# CC3200 register map
Vendor: Texas Instruments; Series: SimpleLink; File version: 1.0
CPU: CM4 r0p1, little endian, MPU, no FPU, 3 interrupt priority bits
Registers are 32-bit, read-write, reset 0x0 unless marked. A register's access mark holds for its fields unless they carry their own. Offsets are from the block's base; [hi:lo] are bit positions; {n}, {i} and the like mark numbered series; 'fields as' and 'values as' point back to an identical list.

## GPIO — GPIOA0
Base 0x40004000
0x00 GPIO_DATA — GPIO_GPIO_DATA
  [7:0] DATA_M
0x400 GPIO_DIR — GPIO_GPIO_DIR
  [7:0] DIR_M
0x404 GPIO_IS — GPIO_GPIO_IS
  [7:0] IS_M
0x408 GPIO_IBE — GPIO_GPIO_IBE
  [7:0] IBE_M
0x40C GPIO_IEV — GPIO_GPIO_IEV
  [7:0] IEV_M
0x410 GPIO_IM — GPIO_GPIO_IM
  [7:0] IME_M
0x414 GPIO_RIS — GPIO_GPIO_RIS
  [7:0] RIS_M
0x418 GPIO_MIS — GPIO_GPIO_MIS
  [7:0] MIS_M
0x41C GPIO_ICR — GPIO_GPIO_ICR
  [7:0] IC_M
0x420 GPIO_AFSEL — GPIO_GPIO_AFSEL
0x500 GPIO_DR2R — GPIO_GPIO_DR2R
  [7:0] DRV2_M
0x504 GPIO_DR4R — GPIO_GPIO_DR4R
  [7:0] DRV4_M
0x508 GPIO_DR8R — GPIO_GPIO_DR8R
  [7:0] DRV8_M
0x50C GPIO_ODR — GPIO_GPIO_ODR
  [7:0] ODE_M
0x510 GPIO_PUR — GPIO_GPIO_PUR
  [7:0] PUE_M
0x514 GPIO_PDR — GPIO_GPIO_PDR
  [7:0] PDE_M
0x518 GPIO_SLR — GPIO_GPIO_SLR
  [7:0] SRL_M
0x51C GPIO_DEN — GPIO_GPIO_DEN
  [7:0] DEN_M
0x520 GPIO_LOCK — GPIO_GPIO_LOCK
  [31:0] LOCK_M
0x524 GPIO_CR — GPIO_GPIO_CR
  [7:0] CR_M
0x528 GPIO_AMSEL — GPIO_GPIO_AMSEL
  [7:0] GPIO_AMSEL_M
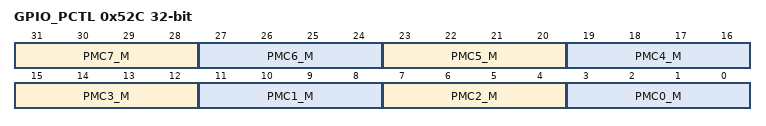
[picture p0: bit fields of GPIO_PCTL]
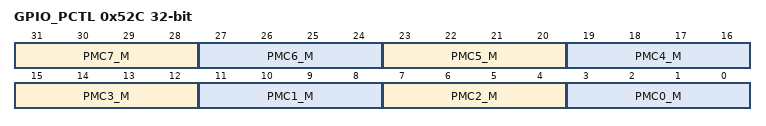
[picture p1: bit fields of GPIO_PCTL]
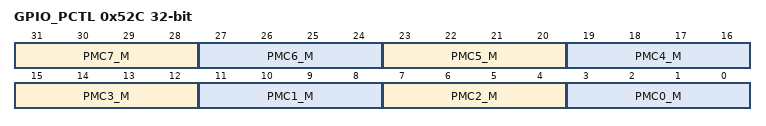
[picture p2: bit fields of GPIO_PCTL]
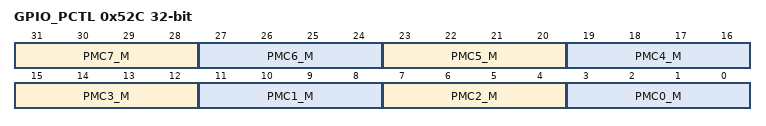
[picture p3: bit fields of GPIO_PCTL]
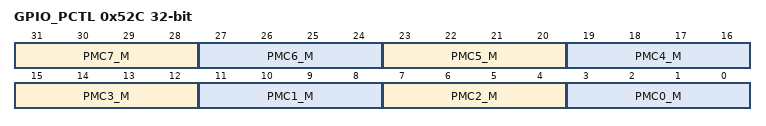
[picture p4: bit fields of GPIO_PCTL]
0x52C GPIO_PCTL — GPIO_GPIO_PCTL
  [4n+3:4n] PMC{n}_M (n=3..7) — GPIO_GPIO_PCTL
  [11:8] PMC1_M — GPIO_GPIO_PCTL
  [7:4] PMC2_M — GPIO_GPIO_PCTL
  [3:0] PMC0_M — GPIO_GPIO_PCTL
0x530 GPIO_ADCCTL — GPIO_GPIO_ADCCTL
  [7:0] ADCEN_M
0x534 GPIO_DMACTL — GPIO_GPIO_DMACTL
  [7:0] DMAEN_M
0x538 GPIO_SI — GPIO_GPIO_SI
  [0] SUM
{0xFC0+4i} GPIO_PERIPHID{i} (i=4..7) — GPIO_GPIO_PERIPHID{i}
  [7:0] PID{i}_M
{0xFE0+4i} GPIO_PERIPHID{i} (i=0..3) — GPIO_GPIO_PERIPHID{i}
  [7:0] PID{i}_M
{0xFF0+4i} GPIO_PCELLID{i} (i=0..3) — GPIO_GPIO_PCELLID{i}
  [7:0] CID{i}_M

## GPIO — GPIOA1
Base 0x40005000
0x00 GPIO_DATA — GPIO_GPIO_DATA
  [7:0] DATA_M
0x400 GPIO_DIR — GPIO_GPIO_DIR
  [7:0] DIR_M
0x404 GPIO_IS — GPIO_GPIO_IS
  [7:0] IS_M
0x408 GPIO_IBE — GPIO_GPIO_IBE
  [7:0] IBE_M
0x40C GPIO_IEV — GPIO_GPIO_IEV
  [7:0] IEV_M
0x410 GPIO_IM — GPIO_GPIO_IM
  [7:0] IME_M
0x414 GPIO_RIS — GPIO_GPIO_RIS
  [7:0] RIS_M
0x418 GPIO_MIS — GPIO_GPIO_MIS
  [7:0] MIS_M
0x41C GPIO_ICR — GPIO_GPIO_ICR
  [7:0] IC_M
0x420 GPIO_AFSEL — GPIO_GPIO_AFSEL
0x500 GPIO_DR2R — GPIO_GPIO_DR2R
  [7:0] DRV2_M
0x504 GPIO_DR4R — GPIO_GPIO_DR4R
  [7:0] DRV4_M
0x508 GPIO_DR8R — GPIO_GPIO_DR8R
  [7:0] DRV8_M
0x50C GPIO_ODR — GPIO_GPIO_ODR
  [7:0] ODE_M
0x510 GPIO_PUR — GPIO_GPIO_PUR
  [7:0] PUE_M
0x514 GPIO_PDR — GPIO_GPIO_PDR
  [7:0] PDE_M
0x518 GPIO_SLR — GPIO_GPIO_SLR
  [7:0] SRL_M
0x51C GPIO_DEN — GPIO_GPIO_DEN
  [7:0] DEN_M
0x520 GPIO_LOCK — GPIO_GPIO_LOCK
  [31:0] LOCK_M
0x524 GPIO_CR — GPIO_GPIO_CR
  [7:0] CR_M
0x528 GPIO_AMSEL — GPIO_GPIO_AMSEL
  [7:0] GPIO_AMSEL_M
0x52C GPIO_PCTL — GPIO_GPIO_PCTL
  fields as GPIO_PCTL
0x530 GPIO_ADCCTL — GPIO_GPIO_ADCCTL
  [7:0] ADCEN_M
0x534 GPIO_DMACTL — GPIO_GPIO_DMACTL
  [7:0] DMAEN_M
0x538 GPIO_SI — GPIO_GPIO_SI
  [0] SUM
{0xFC0+4i} GPIO_PERIPHID{i} (i=4..7) — GPIO_GPIO_PERIPHID{i}
  [7:0] PID{i}_M
{0xFE0+4i} GPIO_PERIPHID{i} (i=0..3) — GPIO_GPIO_PERIPHID{i}
  [7:0] PID{i}_M
{0xFF0+4i} GPIO_PCELLID{i} (i=0..3) — GPIO_GPIO_PCELLID{i}
  [7:0] CID{i}_M

## GPIO — GPIOA2
Base 0x40006000
0x00 GPIO_DATA — GPIO_GPIO_DATA
  [7:0] DATA_M
0x400 GPIO_DIR — GPIO_GPIO_DIR
  [7:0] DIR_M
0x404 GPIO_IS — GPIO_GPIO_IS
  [7:0] IS_M
0x408 GPIO_IBE — GPIO_GPIO_IBE
  [7:0] IBE_M
0x40C GPIO_IEV — GPIO_GPIO_IEV
  [7:0] IEV_M
0x410 GPIO_IM — GPIO_GPIO_IM
  [7:0] IME_M
0x414 GPIO_RIS — GPIO_GPIO_RIS
  [7:0] RIS_M
0x418 GPIO_MIS — GPIO_GPIO_MIS
  [7:0] MIS_M
0x41C GPIO_ICR — GPIO_GPIO_ICR
  [7:0] IC_M
0x420 GPIO_AFSEL — GPIO_GPIO_AFSEL
0x500 GPIO_DR2R — GPIO_GPIO_DR2R
  [7:0] DRV2_M
0x504 GPIO_DR4R — GPIO_GPIO_DR4R
  [7:0] DRV4_M
0x508 GPIO_DR8R — GPIO_GPIO_DR8R
  [7:0] DRV8_M
0x50C GPIO_ODR — GPIO_GPIO_ODR
  [7:0] ODE_M
0x510 GPIO_PUR — GPIO_GPIO_PUR
  [7:0] PUE_M
0x514 GPIO_PDR — GPIO_GPIO_PDR
  [7:0] PDE_M
0x518 GPIO_SLR — GPIO_GPIO_SLR
  [7:0] SRL_M
0x51C GPIO_DEN — GPIO_GPIO_DEN
  [7:0] DEN_M
0x520 GPIO_LOCK — GPIO_GPIO_LOCK
  [31:0] LOCK_M
0x524 GPIO_CR — GPIO_GPIO_CR
  [7:0] CR_M
0x528 GPIO_AMSEL — GPIO_GPIO_AMSEL
  [7:0] GPIO_AMSEL_M
0x52C GPIO_PCTL — GPIO_GPIO_PCTL
  fields as GPIO_PCTL
0x530 GPIO_ADCCTL — GPIO_GPIO_ADCCTL
  [7:0] ADCEN_M
0x534 GPIO_DMACTL — GPIO_GPIO_DMACTL
  [7:0] DMAEN_M
0x538 GPIO_SI — GPIO_GPIO_SI
  [0] SUM
{0xFC0+4i} GPIO_PERIPHID{i} (i=4..7) — GPIO_GPIO_PERIPHID{i}
  [7:0] PID{i}_M
{0xFE0+4i} GPIO_PERIPHID{i} (i=0..3) — GPIO_GPIO_PERIPHID{i}
  [7:0] PID{i}_M
{0xFF0+4i} GPIO_PCELLID{i} (i=0..3) — GPIO_GPIO_PCELLID{i}
  [7:0] CID{i}_M

## GPIO — GPIOA3
Base 0x40007000
0x00 GPIO_DATA — GPIO_GPIO_DATA
  [7:0] DATA_M
0x400 GPIO_DIR — GPIO_GPIO_DIR
  [7:0] DIR_M
0x404 GPIO_IS — GPIO_GPIO_IS
  [7:0] IS_M
0x408 GPIO_IBE — GPIO_GPIO_IBE
  [7:0] IBE_M
0x40C GPIO_IEV — GPIO_GPIO_IEV
  [7:0] IEV_M
0x410 GPIO_IM — GPIO_GPIO_IM
  [7:0] IME_M
0x414 GPIO_RIS — GPIO_GPIO_RIS
  [7:0] RIS_M
0x418 GPIO_MIS — GPIO_GPIO_MIS
  [7:0] MIS_M
0x41C GPIO_ICR — GPIO_GPIO_ICR
  [7:0] IC_M
0x420 GPIO_AFSEL — GPIO_GPIO_AFSEL
0x500 GPIO_DR2R — GPIO_GPIO_DR2R
  [7:0] DRV2_M
0x504 GPIO_DR4R — GPIO_GPIO_DR4R
  [7:0] DRV4_M
0x508 GPIO_DR8R — GPIO_GPIO_DR8R
  [7:0] DRV8_M
0x50C GPIO_ODR — GPIO_GPIO_ODR
  [7:0] ODE_M
0x510 GPIO_PUR — GPIO_GPIO_PUR
  [7:0] PUE_M
0x514 GPIO_PDR — GPIO_GPIO_PDR
  [7:0] PDE_M
0x518 GPIO_SLR — GPIO_GPIO_SLR
  [7:0] SRL_M
0x51C GPIO_DEN — GPIO_GPIO_DEN
  [7:0] DEN_M
0x520 GPIO_LOCK — GPIO_GPIO_LOCK
  [31:0] LOCK_M
0x524 GPIO_CR — GPIO_GPIO_CR
  [7:0] CR_M
0x528 GPIO_AMSEL — GPIO_GPIO_AMSEL
  [7:0] GPIO_AMSEL_M
0x52C GPIO_PCTL — GPIO_GPIO_PCTL
  fields as GPIO_PCTL
0x530 GPIO_ADCCTL — GPIO_GPIO_ADCCTL
  [7:0] ADCEN_M
0x534 GPIO_DMACTL — GPIO_GPIO_DMACTL
  [7:0] DMAEN_M
0x538 GPIO_SI — GPIO_GPIO_SI
  [0] SUM
{0xFC0+4i} GPIO_PERIPHID{i} (i=4..7) — GPIO_GPIO_PERIPHID{i}
  [7:0] PID{i}_M
{0xFE0+4i} GPIO_PERIPHID{i} (i=0..3) — GPIO_GPIO_PERIPHID{i}
  [7:0] PID{i}_M
{0xFF0+4i} GPIO_PCELLID{i} (i=0..3) — GPIO_GPIO_PCELLID{i}
  [7:0] CID{i}_M

## GPIO — GPIOA4
Base 0x40024000
0x00 GPIO_DATA — GPIO_GPIO_DATA
  [7:0] DATA_M
0x400 GPIO_DIR — GPIO_GPIO_DIR
  [7:0] DIR_M
0x404 GPIO_IS — GPIO_GPIO_IS
  [7:0] IS_M
0x408 GPIO_IBE — GPIO_GPIO_IBE
  [7:0] IBE_M
0x40C GPIO_IEV — GPIO_GPIO_IEV
  [7:0] IEV_M
0x410 GPIO_IM — GPIO_GPIO_IM
  [7:0] IME_M
0x414 GPIO_RIS — GPIO_GPIO_RIS
  [7:0] RIS_M
0x418 GPIO_MIS — GPIO_GPIO_MIS
  [7:0] MIS_M
0x41C GPIO_ICR — GPIO_GPIO_ICR
  [7:0] IC_M
0x420 GPIO_AFSEL — GPIO_GPIO_AFSEL
0x500 GPIO_DR2R — GPIO_GPIO_DR2R
  [7:0] DRV2_M
0x504 GPIO_DR4R — GPIO_GPIO_DR4R
  [7:0] DRV4_M
0x508 GPIO_DR8R — GPIO_GPIO_DR8R
  [7:0] DRV8_M
0x50C GPIO_ODR — GPIO_GPIO_ODR
  [7:0] ODE_M
0x510 GPIO_PUR — GPIO_GPIO_PUR
  [7:0] PUE_M
0x514 GPIO_PDR — GPIO_GPIO_PDR
  [7:0] PDE_M
0x518 GPIO_SLR — GPIO_GPIO_SLR
  [7:0] SRL_M
0x51C GPIO_DEN — GPIO_GPIO_DEN
  [7:0] DEN_M
0x520 GPIO_LOCK — GPIO_GPIO_LOCK
  [31:0] LOCK_M
0x524 GPIO_CR — GPIO_GPIO_CR
  [7:0] CR_M
0x528 GPIO_AMSEL — GPIO_GPIO_AMSEL
  [7:0] GPIO_AMSEL_M
0x52C GPIO_PCTL — GPIO_GPIO_PCTL
  fields as GPIO_PCTL
0x530 GPIO_ADCCTL — GPIO_GPIO_ADCCTL
  [7:0] ADCEN_M
0x534 GPIO_DMACTL — GPIO_GPIO_DMACTL
  [7:0] DMAEN_M
0x538 GPIO_SI — GPIO_GPIO_SI
  [0] SUM
{0xFC0+4i} GPIO_PERIPHID{i} (i=4..7) — GPIO_GPIO_PERIPHID{i}
  [7:0] PID{i}_M
{0xFE0+4i} GPIO_PERIPHID{i} (i=0..3) — GPIO_GPIO_PERIPHID{i}
  [7:0] PID{i}_M
{0xFF0+4i} GPIO_PCELLID{i} (i=0..3) — GPIO_GPIO_PCELLID{i}
  [7:0] CID{i}_M
